VERSION "CanViewer Demo 1.1"

NS_ :

BS_:

BU_: ECM TCM ABS IC Tester BCM

VAL_TABLE_ GearPositions 15 "Reverse" 0 "Neutral" 1 "Gear 1" 2 "Gear 2" 3 "Gear 3" 4 "Gear 4" 5 "Gear 5" 6 "Gear 6" 7 "Gear 7" ;
VAL_TABLE_ OnOff 0 "Off" 1 "On" ;

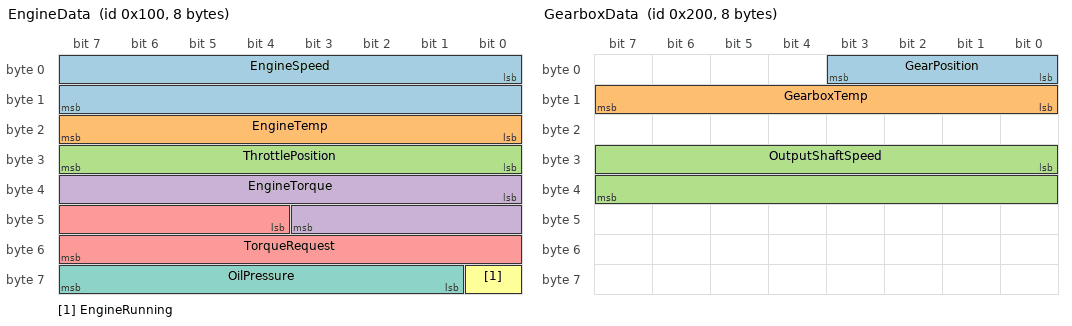
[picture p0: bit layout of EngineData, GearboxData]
BO_ 256 EngineData: 8 ECM
 SG_ EngineSpeed : 0|16@1+ (0.25,0) [0|16383.75] "rpm"  TCM,ABS,IC
 SG_ EngineTemp : 16|8@1+ (1,-50) [-50|205] "degC"  IC
 SG_ ThrottlePosition : 24|8@1+ (0.4,0) [0|100] "%"  TCM
 SG_ EngineTorque : 32|12@1+ (0.5,0) [0|2047.5] "Nm"  TCM,ABS
 SG_ TorqueRequest : 44|12@1- (0.5,0) [-1024|1023.5] "Nm"  TCM
 SG_ EngineRunning : 56|1@1+ (1,0) [0|1] ""  IC
 SG_ OilPressure : 57|7@1+ (0.1,0) [0|12.7] "bar"  IC

BO_ 512 GearboxData: 8 TCM
 SG_ GearPosition : 0|4@1+ (1,0) [0|15] ""  IC,ECM
 SG_ GearboxTemp : 8|8@1+ (1,-40) [-40|215] "degC"  IC
 SG_ OutputShaftSpeed : 24|16@1+ (0.125,0) [0|8191.875] "rpm"  ECM,ABS

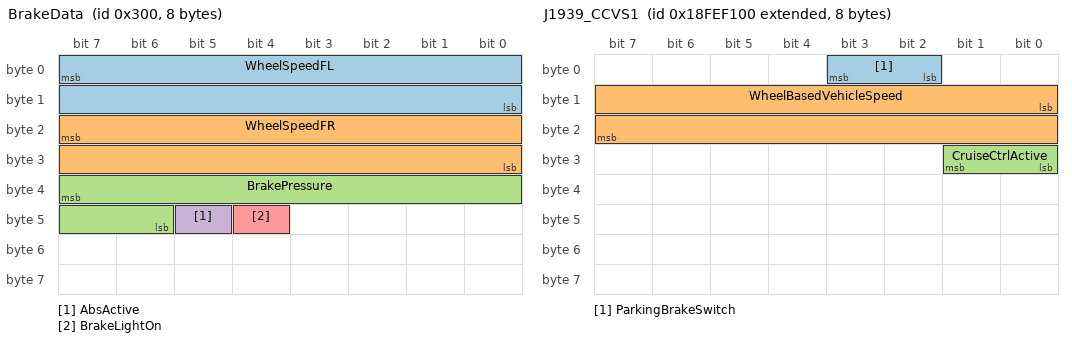
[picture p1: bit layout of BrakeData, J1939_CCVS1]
BO_ 768 BrakeData: 8 ABS
 SG_ WheelSpeedFL : 7|16@0+ (0.01,0) [0|655.35] "km/h"  IC,ECM
 SG_ WheelSpeedFR : 23|16@0+ (0.01,0) [0|655.35] "km/h"  IC,ECM
 SG_ BrakePressure : 39|10@0+ (0.5,0) [0|511.5] "bar"  ECM
 SG_ AbsActive : 45|1@0+ (1,0) [0|1] ""  IC
 SG_ BrakeLightOn : 44|1@0+ (1,0) [0|1] ""  BCM

BO_ 1024 DiagData: 8 Tester
 SG_ MuxSelector M : 0|8@1+ (1,0) [0|255] ""  ECM
 SG_ SensorVoltage m0 : 8|16@1+ (0.001,0) [0|65.535] "V"  ECM
 SG_ SensorCurrent m1 : 8|16@1+ (0.01,0) [0|655.35] "A"  ECM
 SG_ ErrorCode m2 : 8|16@1+ (1,0) [0|65535] ""  ECM

BO_ 1280 BatteryData: 8 ECM
 SG_ BatteryVoltage : 0|32@1- (1,0) [0|100] "V"  IC
 SG_ Consumption : 32|16@1+ (0.1,0) [0|6553.5] "l/h"  IC

BO_ 2364539904 J1939_EEC1: 8 ECM
 SG_ ActualEnginePercentTorque : 16|8@1+ (1,-125) [-125|125] "%"  Vector__XXX
 SG_ EngineSpeedJ1939 : 24|16@1+ (0.125,0) [0|8031.875] "rpm"  Vector__XXX

BO_ 2566844672 J1939_CCVS1: 8 ECM
 SG_ ParkingBrakeSwitch : 2|2@1+ (1,0) [0|3] ""  IC
 SG_ WheelBasedVehicleSpeed : 8|16@1+ (0.00390625,0) [0|250.996] "km/h"  IC
 SG_ CruiseCtrlActive : 24|2@1+ (1,0) [0|3] ""  IC

BO_ 1536 AdasObjects: 24 ECM
 SG_ ObjCount : 0|4@1+ (1,0) [0|15] ""  IC
 SG_ Obj1Dist : 8|16@1+ (0.01,0) [0|655.35] "m"  IC,ABS
 SG_ Obj1Speed : 24|16@1- (0.01,0) [-327.68|327.67] "m/s"  ABS
 SG_ Obj1Angle : 40|16@1- (0.1,0) [-3276.8|3276.7] "deg"  IC
 SG_ Obj2Dist : 56|16@1+ (0.01,0) [0|655.35] "m"  IC,ABS
 SG_ Obj2Speed : 72|16@1- (0.01,0) [-327.68|327.67] "m/s"  ABS

BO_ 1792 BodyStatus: 2 BCM
 SG_ DoorOpen : 0|4@1+ (1,0) [0|15] ""  IC
 SG_ HeadlightsOn : 4|1@1+ (1,0) [0|1] ""  IC

BO_TX_BU_ 512 : TCM,ECM;

CM_ "CanViewer demo database with typical powertrain messages.";
CM_ BU_ ECM "Engine Control Module";
CM_ BU_ TCM "Transmission Control Module";
CM_ BU_ ABS "Anti-lock Braking System";
CM_ BU_ IC "Instrument Cluster";
CM_ BU_ BCM "Body Control Module";
CM_ BO_ 256 "Engine status broadcast, 10 ms cycle.";
CM_ SG_ 256 EngineSpeed "Crankshaft rotational speed, filtered.";
CM_ BO_ 1024 "Diagnostic data message.
Second line of this comment.";
CM_ SG_ 768 BrakePressure "Master cylinder pressure.";
CM_ BO_ 1536 "ADAS object list broadcast (CAN FD, 24-byte payload).";
CM_ BO_ 1792 "Door and light status.";

BA_DEF_ BO_ "GenMsgCycleTime" INT 0 10000;
BA_DEF_ BO_ "GenMsgSendType" ENUM "Cyclic","Event","IfActive","NoMsgSendType";
BA_DEF_ SG_ "GenSigStartValue" FLOAT 0 100000;
BA_DEF_ BU_ "NodeAddress" HEX 0 255;
BA_DEF_ "BusType" STRING;
BA_DEF_ BO_ "VFrameFormat" ENUM "StandardCAN","ExtendedCAN","reserved","J1939PG","reserved","reserved","reserved","reserved","reserved","reserved","reserved","reserved","reserved","reserved","StandardCAN_FD","ExtendedCAN_FD";
BA_DEF_DEF_ "VFrameFormat" 0;
BA_DEF_DEF_ "GenMsgCycleTime" 0;
BA_DEF_DEF_ "GenMsgSendType" 3;
BA_DEF_DEF_ "GenSigStartValue" 0;
BA_DEF_DEF_ "NodeAddress" 0;
BA_DEF_DEF_ "BusType" "CAN";
BA_ "GenMsgCycleTime" BO_ 256 10;
BA_ "GenMsgCycleTime" BO_ 512 20;
BA_ "GenMsgCycleTime" BO_ 768 10;
BA_ "GenMsgSendType" BO_ 256 0;
BA_ "GenMsgSendType" BO_ 1024 1;
BA_ "NodeAddress" BU_ ECM 16;
BA_ "NodeAddress" BU_ TCM 24;
BA_ "NodeAddress" BU_ BCM 40;
BA_ "GenMsgCycleTime" BO_ 1536 50;
BA_ "VFrameFormat" BO_ 1536 14;
BA_ "VFrameFormat" BO_ 2364539904 3;
BA_ "VFrameFormat" BO_ 2566844672 3;
BA_ "GenMsgCycleTime" BO_ 2566844672 100;
BA_ "GenMsgCycleTime" BO_ 1792 100;

VAL_ 512 GearPosition 15 "Reverse" 0 "Neutral" 1 "Gear 1" 2 "Gear 2" 3 "Gear 3" 4 "Gear 4" 5 "Gear 5" 6 "Gear 6" 7 "Gear 7" ;
VAL_ 256 EngineRunning 0 "Stopped" 1 "Running" ;
VAL_ 768 AbsActive 0 "Inactive" 1 "Active" ;
VAL_ 1024 ErrorCode 0 "No error" 1 "Sensor short to ground" 2 "Sensor short to battery" 3 "Sensor open circuit" ;

SIG_VALTYPE_ 1280 BatteryVoltage : 1;

SG_MUL_VAL_ 1024 ErrorCode MuxSelector 2-2;
